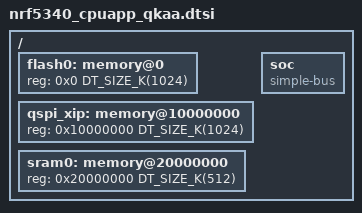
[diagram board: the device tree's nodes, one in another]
/*
 * Copyright (c) 2020 Nordic Semiconductor ASA
 *
 * SPDX-License-Identifier: Apache-2.0
 */

#include <mem.h>
#include <nordic/nrf5340_cpuapp.dtsi>

/ {
	flash0: memory@0 {
		device_type = "memory";
		reg = <0x0 DT_SIZE_K(1024)>;
		#address-cells = <1>;
		#size-cells = <1>;
		ranges = <0x0 0x10000000 DT_SIZE_K(1024)>;
	};

	qspi_xip: memory@10000000 {
		device_type = "memory";
		reg = <0x10000000 DT_SIZE_K(1024)>;
		#address-cells = <1>;
		#size-cells = <1>;
		ranges = <0x0 0x10000000 DT_SIZE_K(1024)>;
	};

	sram0: memory@20000000 {
		device_type = "memory";
		reg = <0x20000000 DT_SIZE_K(512)>;
		#address-cells = <1>;
		#size-cells = <1>;
		ranges = <0x0 0x20000000 DT_SIZE_K(512)>;
	};

	soc {
		compatible = "simple-bus";
	};
};
